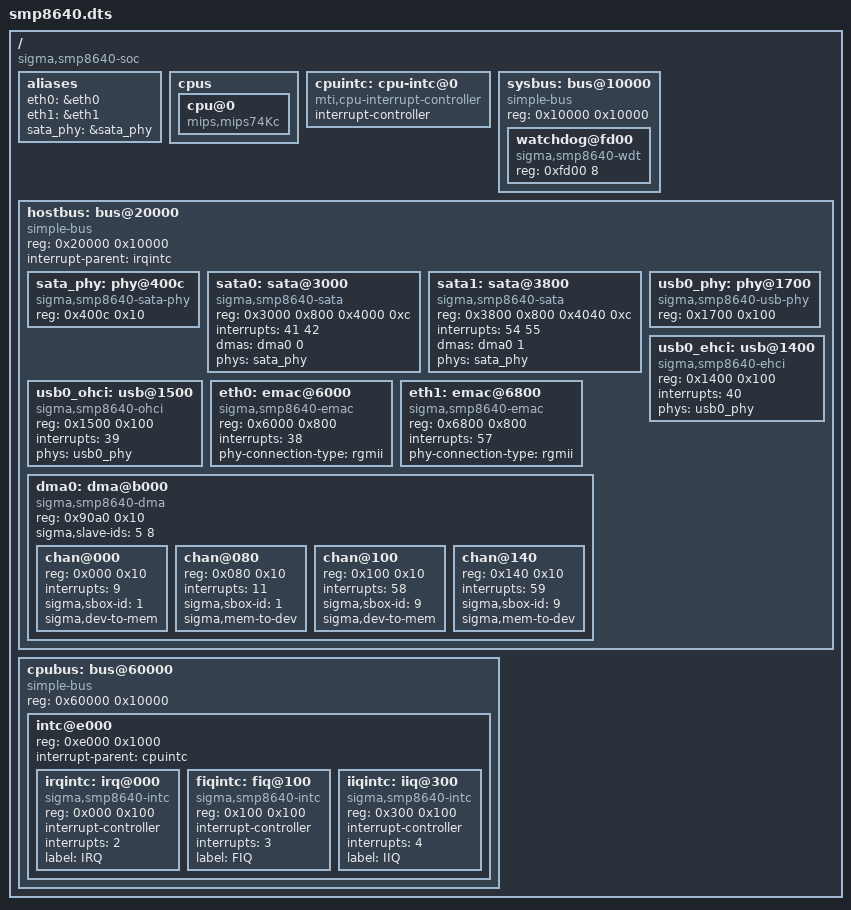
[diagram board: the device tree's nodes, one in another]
/dts-v1/;

/ {
	compatible = "sigma,smp8640-soc";

	#address-cells = <1>;
	#size-cells = <1>;

	aliases {
		eth0 = &eth0;
		eth1 = &eth1;
		sata_phy = &sata_phy;
	};

	cpus {
		cpu@0 {
			compatible = "mips,mips74Kc";
		};
	};

	cpuintc: cpu-intc@0 {
		compatible = "mti,cpu-interrupt-controller";
		#address-cells = <0>;
		interrupt-controller;
		#interrupt-cells = <1>;
	};

	sysbus: bus@10000 {
		compatible = "simple-bus";
		reg = <0x10000 0x10000>;
		ranges = <0x0 0x10000 0x10000>;

		#address-cells = <1>;
		#size-cells = <1>;

		watchdog@fd00 {
			compatible = "sigma,smp8640-wdt";
			reg = <0xfd00 8>;
		};
	};

	hostbus: bus@20000 {
		compatible = "simple-bus";
		reg = <0x20000 0x10000>;
		ranges = <0x0 0x20000 0x10000>;
		interrupt-parent = <&irqintc>;

		#address-cells = <1>;
		#size-cells = <1>;

		sata_phy: phy@400c {
			compatible = "sigma,smp8640-sata-phy";
			reg = <0x400c 0x10>;
			#phy-cells = <0>;
		};

		sata0: sata@3000 {
			compatible = "sigma,smp8640-sata";
			reg = <0x3000 0x800 0x4000 0xc>;
			interrupts = <41 42>;
			dmas = <&dma0 0>;
			dma-names = "sata";
			phys = <&sata_phy>;
			phy-names = "sata";
		};

		sata1: sata@3800 {
			compatible = "sigma,smp8640-sata";
			reg = <0x3800 0x800 0x4040 0xc>;
			interrupts = <54 55>;
			dmas = <&dma0 1>;
			dma-names = "sata";
			phys = <&sata_phy>;
			phy-names = "sata";
		};

		usb0_phy: phy@1700 {
			compatible = "sigma,smp8640-usb-phy";
			reg = <0x1700 0x100>;
			#phy-cells = <0>;
		};

		usb0_ehci: usb@1400 {
			compatible = "sigma,smp8640-ehci", "generic-ehci";
			reg = <0x1400 0x100>;
			interrupts = <40>;
			phys = <&usb0_phy>;
			phy-names = "usb";
		};

		usb0_ohci: usb@1500 {
			compatible = "sigma,smp8640-ohci", "generic-ohci";
			reg = <0x1500 0x100>;
			interrupts = <39>;
			phys = <&usb0_phy>;
			phy-names = "usb";
		};

		eth0: emac@6000 {
			compatible = "sigma,smp8640-emac";
			reg = <0x6000 0x800>;
			interrupts = <38>;
			phy-connection-type = "rgmii";
		};

		eth1: emac@6800 {
			compatible = "sigma,smp8640-emac";
			reg = <0x6800 0x800>;
			interrupts = <57>;
			phy-connection-type = "rgmii";
		};

		dma0: dma@b000 {
			compatible = "sigma,smp8640-dma";
			reg = <0x90a0 0x10>;
			ranges = <0x0 0xb000 0x200>;
			#dma-cells = <1>;
			sigma,slave-ids = <5 8>;
			#address-cells = <1>;
			#size-cells = <1>;

			chan@000 {
				reg = <0x000 0x10>;
				interrupts = <9>;
				sigma,sbox-id = <1>;
				sigma,dev-to-mem;
			};

			chan@080 {
				reg = <0x080 0x10>;
				interrupts = <11>;
				sigma,sbox-id = <1>;
				sigma,mem-to-dev;
			};

			chan@100 {
				reg = <0x100 0x10>;
				interrupts = <58>;
				sigma,sbox-id = <9>;
				sigma,dev-to-mem;
			};

			chan@140 {
				reg = <0x140 0x10>;
				interrupts = <59>;
				sigma,sbox-id = <9>;
				sigma,mem-to-dev;
			};
		};
	};

	cpubus: bus@60000 {
		compatible = "simple-bus";
		reg = <0x60000 0x10000>;
		ranges = <0x0 0x60000 0x10000>;

		#address-cells = <1>;
		#size-cells = <1>;

		intc@e000 {
			reg = <0xe000 0x1000>;
			ranges = <0x0 0xe000 0x1000>;
			interrupt-parent = <&cpuintc>;

			#address-cells = <1>;
			#size-cells = <1>;

			irqintc: irq@000 {
				compatible = "sigma,smp8640-intc";
				reg = <0x000 0x100>;
				interrupt-controller;
				#interrupt-cells = <1>;
				interrupts = <2>;
				label = "IRQ";
			};

			fiqintc: fiq@100 {
				compatible = "sigma,smp8640-intc";
				reg = <0x100 0x100>;
				interrupt-controller;
				#interrupt-cells = <1>;
				interrupts = <3>;
				label = "FIQ";
			};

			iiqintc: iiq@300 {
				compatible = "sigma,smp8640-intc";
				reg = <0x300 0x100>;
				interrupt-controller;
				#interrupt-cells = <1>;
				interrupts = <4>;
				label = "IIQ";
			};
		};
	};
};
